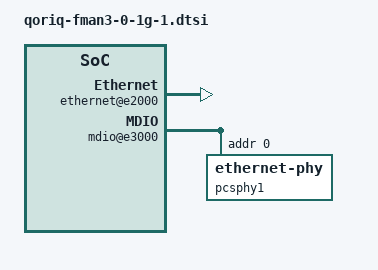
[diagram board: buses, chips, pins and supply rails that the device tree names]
// SPDX-License-Identifier: (GPL-2.0+ OR BSD-3-Clause)
/*
 * QorIQ FMan v3 1g port #1 device tree
 *
 * Copyright 2012-2015 Freescale Semiconductor Inc.
 *
 */

fman@1a00000 {
	fman0_rx_0x09: port@89000 {
		cell-index = <0x9>;
		compatible = "fsl,fman-v3-port-rx";
		reg = <0x89000 0x1000>;
	};

	fman0_tx_0x29: port@a9000 {
		cell-index = <0x29>;
		compatible = "fsl,fman-v3-port-tx";
		reg = <0xa9000 0x1000>;
	};

	ethernet@e2000 {
		cell-index = <1>;
		compatible = "fsl,fman-memac";
		reg = <0xe2000 0x1000>;
		fsl,fman-ports = <&fman0_rx_0x09 &fman0_tx_0x29>;
		ptp-timer = <&ptp_timer0>;
		pcsphy-handle = <&pcsphy1>;
	};

	mdio@e3000 {
		#address-cells = <1>;
		#size-cells = <0>;
		compatible = "fsl,fman-memac-mdio", "fsl,fman-xmdio";
		reg = <0xe3000 0x1000>;

		pcsphy1: ethernet-phy@0 {
			reg = <0x0>;
		};
	};
};
